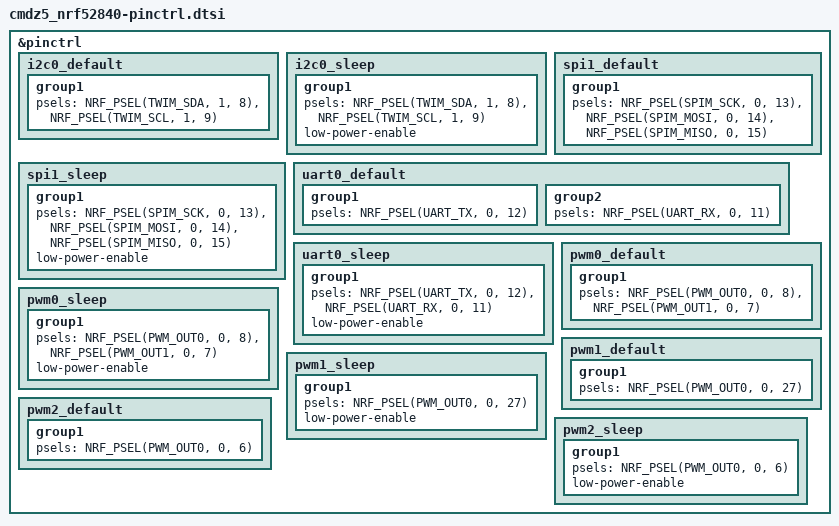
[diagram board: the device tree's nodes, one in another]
/*
 * Pin assignment, see the GPIO table in ../../../../board/README.md.
 */

&pinctrl {
	i2c0_default: i2c0_default {
		group1 {
			psels = <NRF_PSEL(TWIM_SDA, 1, 8)>,
				<NRF_PSEL(TWIM_SCL, 1, 9)>;
		};
	};

	i2c0_sleep: i2c0_sleep {
		group1 {
			psels = <NRF_PSEL(TWIM_SDA, 1, 8)>,
				<NRF_PSEL(TWIM_SCL, 1, 9)>;
			low-power-enable;
		};
	};

	spi1_default: spi1_default {
		group1 {
			psels = <NRF_PSEL(SPIM_SCK, 0, 13)>,
				<NRF_PSEL(SPIM_MOSI, 0, 14)>,
				<NRF_PSEL(SPIM_MISO, 0, 15)>;
		};
	};

	spi1_sleep: spi1_sleep {
		group1 {
			psels = <NRF_PSEL(SPIM_SCK, 0, 13)>,
				<NRF_PSEL(SPIM_MOSI, 0, 14)>,
				<NRF_PSEL(SPIM_MISO, 0, 15)>;
			low-power-enable;
		};
	};

	uart0_default: uart0_default {
		group1 {
			psels = <NRF_PSEL(UART_TX, 0, 12)>;
		};
		group2 {
			psels = <NRF_PSEL(UART_RX, 0, 11)>;
		};
	};

	uart0_sleep: uart0_sleep {
		group1 {
			psels = <NRF_PSEL(UART_TX, 0, 12)>,
				<NRF_PSEL(UART_RX, 0, 11)>;
			low-power-enable;
		};
	};

	/* Backlight LEDs (channel 0) and vibration motor (channel 1). */
	pwm0_default: pwm0_default {
		group1 {
			psels = <NRF_PSEL(PWM_OUT0, 0, 8)>,
				<NRF_PSEL(PWM_OUT1, 0, 7)>;
		};
	};

	pwm0_sleep: pwm0_sleep {
		group1 {
			psels = <NRF_PSEL(PWM_OUT0, 0, 8)>,
				<NRF_PSEL(PWM_OUT1, 0, 7)>;
			low-power-enable;
		};
	};

	/* Loudspeaker. */
	pwm1_default: pwm1_default {
		group1 {
			psels = <NRF_PSEL(PWM_OUT0, 0, 27)>;
		};
	};

	pwm1_sleep: pwm1_sleep {
		group1 {
			psels = <NRF_PSEL(PWM_OUT0, 0, 27)>;
			low-power-enable;
		};
	};

	/* Earpiece (RC filter into the PAM8302). */
	pwm2_default: pwm2_default {
		group1 {
			psels = <NRF_PSEL(PWM_OUT0, 0, 6)>;
		};
	};

	pwm2_sleep: pwm2_sleep {
		group1 {
			psels = <NRF_PSEL(PWM_OUT0, 0, 6)>;
			low-power-enable;
		};
	};
};
